# MKE15D7 register map
File version: 1.6
Registers are 32-bit, read-write, reset 0x0 unless marked. A register's access mark holds for its fields unless they carry their own. Offsets are from the block's base; [hi:lo] are bit positions; {n}, {i} and the like mark numbered series; 'fields as' and 'values as' point back to an identical list.

## AIPS — AIPS-Lite Bridge
Base 0x40000000; register names take the prefix AIPS_
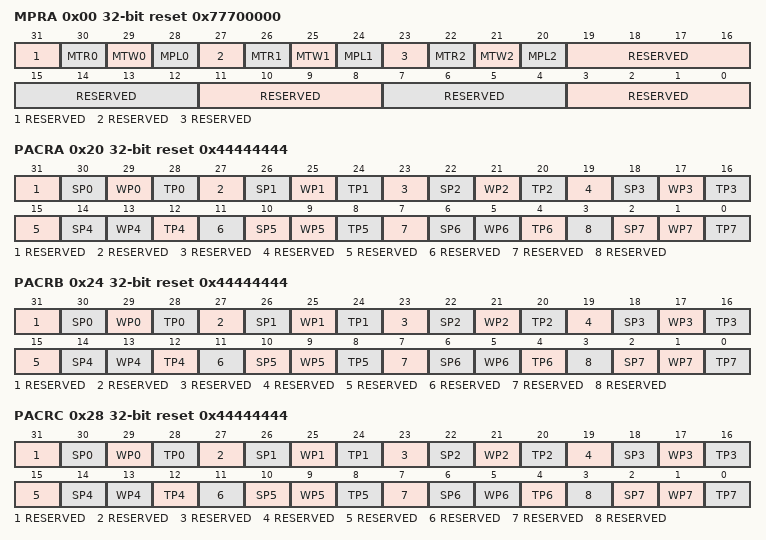
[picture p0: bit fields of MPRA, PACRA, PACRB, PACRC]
0x00 MPRA reset 0x77700000 — Master Privilege Register A
  [31] RESERVED ro
  [30] MTR0 — Master Trusted For Read
    0=This master is not trusted for read accesses; 1=This master is trusted for read accesses
  [29] MTW0 — Master Trusted For Writes
    0=This master is not trusted for write accesses; 1=This master is trusted for write accesses
  [28] MPL0 — Master Privilege Level
    0=Accesses from this master are forced to user-mode; 1=Accesses from this master are not forced to user-mode
  [27] RESERVED ro
  [26] MTR1 — Master trusted for read
    values as MTR0
  [25] MTW1 — Master trusted for writes
    values as MTW0
  [24] MPL1 — Master privilege level
    values as MPL0
  [23] RESERVED ro
  [22] MTR2 — Master Trusted For Read
    values as MTR0
  [21] MTW2 — Master Trusted For Writes
    values as MTW0
  [20] MPL2 — Master Privilege Level
    values as MPL0
  [19:16] RESERVED ro
  [15:12] RESERVED ro
  [11:8] RESERVED ro
  [7:4] RESERVED ro
  [3:0] RESERVED ro
0x20 PACRA reset 0x44444444 — Peripheral Access Control Register
  [31] RESERVED ro
  [30] SP0 — Supervisor Protect
    0=This peripheral does not require supervisor privilege level for accesses; 1=This peripheral requires supervisor privilege level for accesses
  [29] WP0 — Write protect
    0=This peripheral allows write accesses; 1=This peripheral is write protected
  [28] TP0 — Trusted Protect
    0=Accesses from an untrusted master are allowed; 1=Accesses from an untrusted master are not allowed
  [27] RESERVED ro
  [26] SP1 — Supervisor Protect
    values as SP0
  [25] WP1 — Write Protect
    values as WP0
  [24] TP1 — Trusted protect
    values as TP0
  [23] RESERVED ro
  [22] SP2 — Supervisor Protect
    values as SP0
  [21] WP2 — Write protect
    values as WP0
  [20] TP2 — Trusted Protect
    values as TP0
  [19] RESERVED ro
  [18] SP3 — Supervisor protect
    values as SP0
  [17] WP3 — Write Protect
    values as WP0
  [16] TP3 — Trusted protect
    values as TP0
  [15] RESERVED ro
  [30-4n] SP{n} (n=4..7) — Supervisor Protect
    values as SP0
  [13] WP4 — Write protect
    values as WP0
  [12] TP4 — Trusted protect
    values as TP0
  [11] RESERVED ro
  [9] WP5 — Write Protect
    values as WP0
  [8] TP5 — Trusted Protect
    values as TP0
  [7] RESERVED ro
  [5] WP6 — Write Protect
    values as WP0
  [4] TP6 — Trusted Protect
    values as TP0
  [3] RESERVED ro
  [1] WP7 — Write Protect
    values as WP0
  [0] TP7 — Trusted Protect
    values as TP0
0x24 PACRB reset 0x44444444 — Peripheral Access Control Register
  fields as PACRA
0x28 PACRC reset 0x44444444 — Peripheral Access Control Register
  fields as PACRA
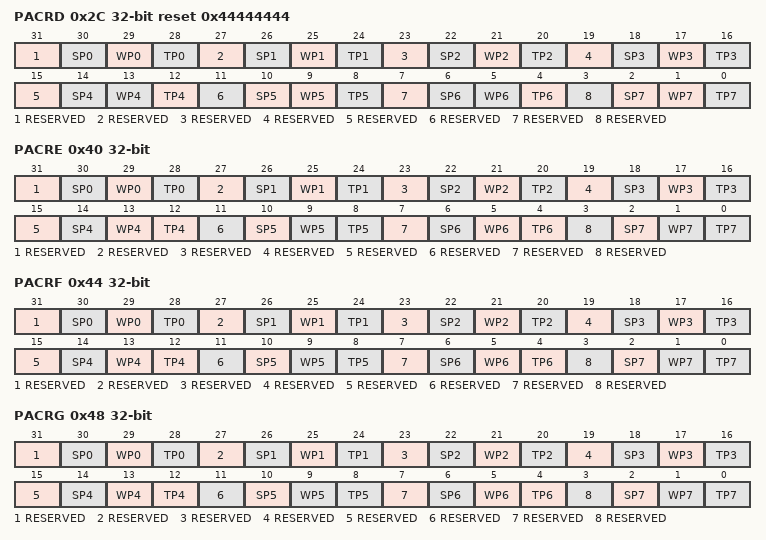
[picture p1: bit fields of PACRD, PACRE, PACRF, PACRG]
0x2C PACRD reset 0x44444444 — Peripheral Access Control Register
  fields as PACRA
0x40 PACRE reset not defined — Peripheral Access Control Register
  [31] RESERVED ro
  [30] SP0 — Supervisor Protect
    values as PACRA.SP0
  [29] WP0 — Write Protect
    values as PACRA.WP0
  [28] TP0 — Trusted protect
    values as PACRA.TP0
  [27] RESERVED ro
  [26] SP1 — Supervisor Protect
    values as PACRA.SP0
  [25] WP1 — Write Protect
    values as PACRA.WP0
  [24] TP1 — Trusted Protect
    values as PACRA.TP0
  [23] RESERVED ro
  [22] SP2 — Supervisor protect
    values as PACRA.SP0
  [21] WP2 — Write Protect
    values as PACRA.WP0
  [20] TP2 — Trusted protect
    values as PACRA.TP0
  [19] RESERVED ro
  [18] SP3 — Supervisor Protect
    values as PACRA.SP0
  [17] WP3 — Write protect
    values as PACRA.WP0
  [16] TP3 — Trusted Protect
    values as PACRA.TP0
  [15] RESERVED ro
  [14] SP4 — Supervisor protect
    values as PACRA.SP0
  [29-4n] WP{n} (n=4..7) — Write Protect
    values as PACRA.WP0
  [12] TP4 — Trusted protect
    values as PACRA.TP0
  [11] RESERVED ro
  [10] SP5 — Supervisor Protect
    values as PACRA.SP0
  [8] TP5 — Trusted Protect
    values as PACRA.TP0
  [7] RESERVED ro
  [6] SP6 — Supervisor Protect
    values as PACRA.SP0
  [4] TP6 — Trusted Protect
    values as PACRA.TP0
  [3] RESERVED ro
  [2] SP7 — Supervisor Protect
    values as PACRA.SP0
  [0] TP7 — Trusted Protect
    values as PACRA.TP0
0x44 PACRF reset not defined — Peripheral Access Control Register
  fields as PACRE
0x48 PACRG reset not defined — Peripheral Access Control Register
  fields as PACRE
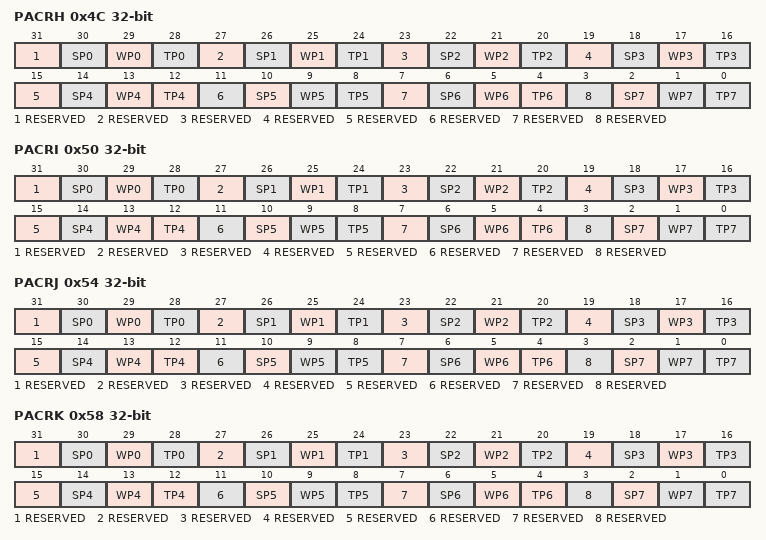
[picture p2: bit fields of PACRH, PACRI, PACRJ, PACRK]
0x4C PACRH reset not defined — Peripheral Access Control Register
  fields as PACRE
0x50 PACRI reset not defined — Peripheral Access Control Register
  fields as PACRE
0x54 PACRJ reset not defined — Peripheral Access Control Register
  fields as PACRE
0x58 PACRK reset not defined — Peripheral Access Control Register
  fields as PACRE
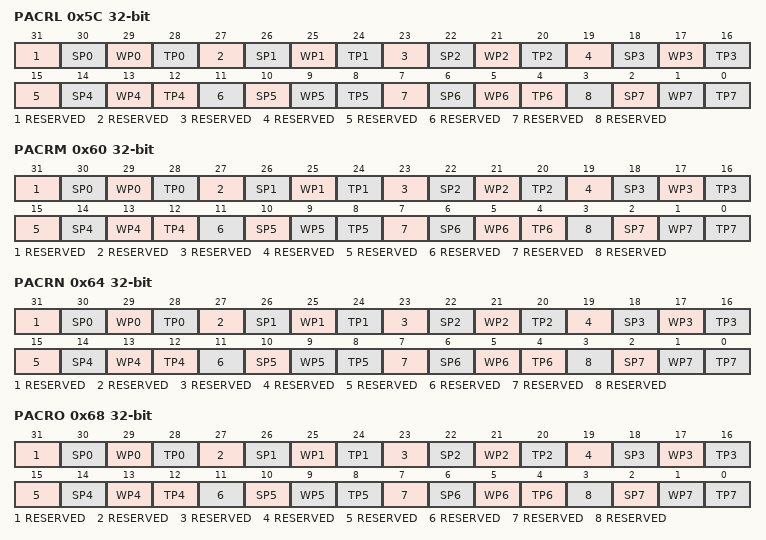
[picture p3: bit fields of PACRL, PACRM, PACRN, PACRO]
0x5C PACRL reset not defined — Peripheral Access Control Register
  fields as PACRE
0x60 PACRM reset not defined — Peripheral Access Control Register
  fields as PACRE
0x64 PACRN reset not defined — Peripheral Access Control Register
  fields as PACRE
0x68 PACRO reset not defined — Peripheral Access Control Register
  fields as PACRE
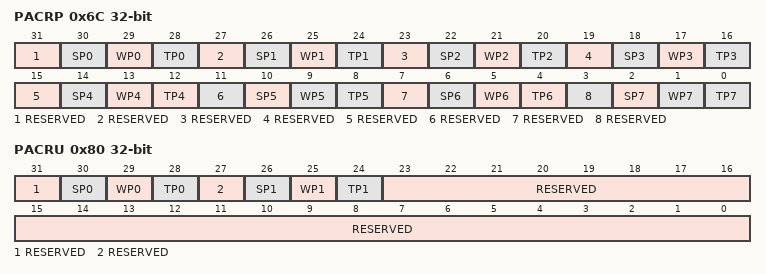
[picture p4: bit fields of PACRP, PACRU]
0x6C PACRP reset not defined — Peripheral Access Control Register
  fields as PACRE
0x80 PACRU reset not defined — Peripheral Access Control Register U
  [31] RESERVED ro
  [30] SP0 — Supervisor protect
    values as PACRA.SP0
  [29] WP0 — Write Protect
    values as PACRA.WP0
  [28] TP0 — Trusted Protect
    values as PACRA.TP0
  [27] RESERVED ro
  [26] SP1 — Supervisor Protect
    values as PACRA.SP0
  [25] WP1 — Write protect
    values as PACRA.WP0
  [24] TP1 — Trusted Protect
    values as PACRA.TP0
  [23:0] RESERVED ro
